# STM32F030 register map
File version: 1.0
Registers are 32-bit, read-write, reset 0x0 unless marked. A register's access mark holds for its fields unless they carry their own. Offsets are from the block's base; [hi:lo] are bit positions; {n}, {i} and the like mark numbered series.

## ADC — Analog-to-digital converter
Base 0x40012400
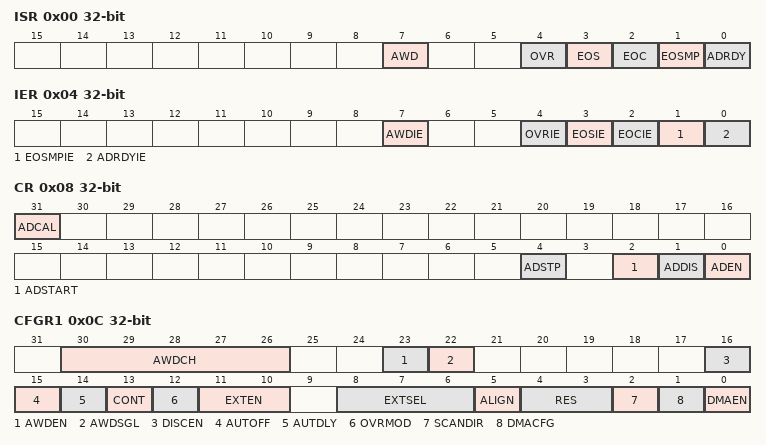
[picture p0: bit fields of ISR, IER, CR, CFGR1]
0x00 ISR — interrupt and status register
  [7] AWD — Analog watchdog flag
  [4] OVR — ADC overrun
  [3] EOS — End of sequence flag
  [2] EOC — End of conversion flag
  [1] EOSMP — End of sampling flag
  [0] ADRDY — ADC ready
0x04 IER — interrupt enable register
  [7] AWDIE — Analog watchdog interrupt enable
  [4] OVRIE — Overrun interrupt enable
  [3] EOSIE — End of conversion sequence interrupt enable
  [2] EOCIE — End of conversion interrupt enable
  [1] EOSMPIE — End of sampling flag interrupt enable
  [0] ADRDYIE — ADC ready interrupt enable
0x08 CR — control register
  [31] ADCAL — ADC calibration
  [4] ADSTP — ADC stop conversion command
  [2] ADSTART — ADC start conversion command
  [1] ADDIS — ADC disable command
  [0] ADEN — ADC enable command
0x0C CFGR1 — configuration register 1
  [30:26] AWDCH — Analog watchdog channel selection
  [23] AWDEN — Analog watchdog enable
  [22] AWDSGL — Enable the watchdog on a single channel or on all channels
  [16] DISCEN — Discontinuous mode
  [15] AUTOFF — Auto-off mode
  [14] AUTDLY — Auto-delayed conversion mode
  [13] CONT — Single / continuous conversion mode
  [12] OVRMOD — Overrun management mode
  [11:10] EXTEN — External trigger enable and polarity selection
  [8:6] EXTSEL — External trigger selection
  [5] ALIGN — Data alignment
  [4:3] RES — Data resolution
  [2] SCANDIR — Scan sequence direction
  [1] DMACFG — Direct memery access configuration
  [0] DMAEN — Direct memory access enable
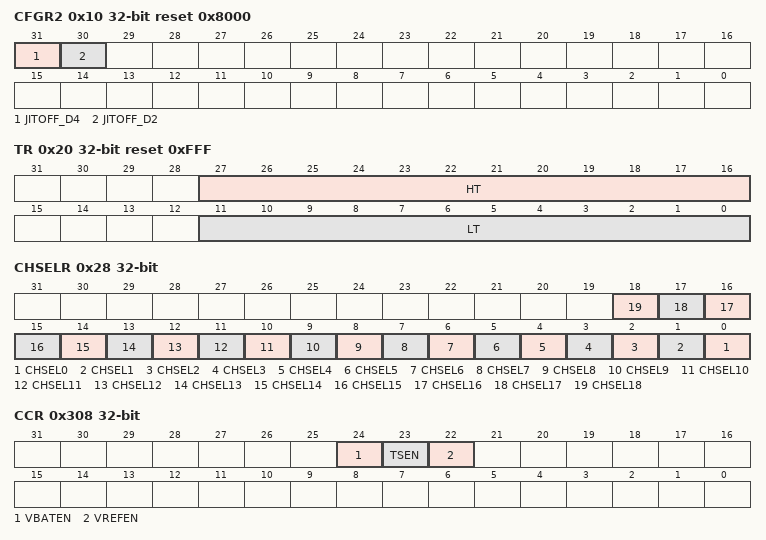
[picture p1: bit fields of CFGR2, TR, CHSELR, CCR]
0x10 CFGR2 reset 0x8000 — configuration register 2
  [31] JITOFF_D4, [30] JITOFF_D2
0x14 SMPR — sampling time register
  [2:0] SMPR — Sampling time selection
0x20 TR reset 0xFFF — watchdog threshold register
  [27:16] HT — Analog watchdog higher threshold
  [11:0] LT — Analog watchdog lower threshold
0x28 CHSELR — channel selection register
  [n] CHSEL{n} (n=0..18) — Channel-x selection
0x40 DR ro — data register
  [15:0] DATA — Converted data
0x308 CCR — common configuration register
  [24] VBATEN — VBAT enable
  [23] TSEN — Temperature sensor enable
  [22] VREFEN — Temperature sensor and VREFINT enable

## TIM16 — General-purpose-timers
Base 0x40014400
Same registers: TIM17 0x40014800
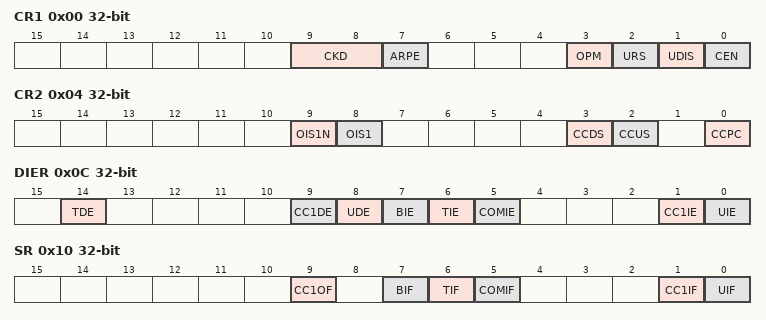
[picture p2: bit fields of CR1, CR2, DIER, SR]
0x00 CR1 — control register 1
  [9:8] CKD — Clock division
  [7] ARPE — Auto-reload preload enable
  [3] OPM — One-pulse mode
  [2] URS — Update request source
  [1] UDIS — Update disable
  [0] CEN — Counter enable
0x04 CR2 — control register 2
  [9] OIS1N — Output Idle state 1
  [8] OIS1 — Output Idle state 1
  [3] CCDS — Capture/compare DMA selection
  [2] CCUS — Capture/compare control update selection
  [0] CCPC — Capture/compare preloaded control
0x0C DIER — DMA/Interrupt enable register
  [14] TDE — Trigger DMA request enable
  [9] CC1DE — Capture/Compare 1 DMA request enable
  [8] UDE — Update DMA request enable
  [7] BIE — Break interrupt enable
  [6] TIE — Trigger interrupt enable
  [5] COMIE — COM interrupt enable
  [1] CC1IE — Capture/Compare 1 interrupt enable
  [0] UIE — Update interrupt enable
0x10 SR — status register
  [9] CC1OF — Capture/Compare 1 overcapture flag
  [7] BIF — Break interrupt flag
  [6] TIF — Trigger interrupt flag
  [5] COMIF — COM interrupt flag
  [1] CC1IF — Capture/compare 1 interrupt flag
  [0] UIF — Update interrupt flag
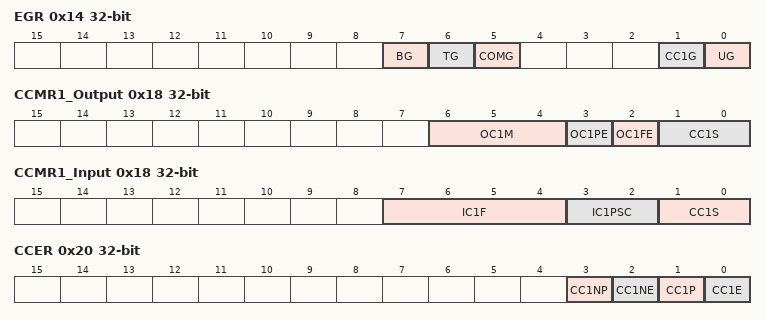
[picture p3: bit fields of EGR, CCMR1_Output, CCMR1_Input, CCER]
0x14 EGR wo — event generation register
  [7] BG — Break generation
  [6] TG — Trigger generation
  [5] COMG — Capture/Compare control update generation
  [1] CC1G — Capture/compare 1 generation
  [0] UG — Update generation
0x18 CCMR1_Output — capture/compare mode register (output mode)
  [6:4] OC1M — Output Compare 1 mode
  [3] OC1PE — Output Compare 1 preload enable
  [2] OC1FE — Output Compare 1 fast enable
  [1:0] CC1S — Capture/Compare 1 selection
0x18 CCMR1_Input (alternate view of CCMR1_Output) — capture/compare mode register 1 (input mode)
  [7:4] IC1F — Input capture 1 filter
  [3:2] IC1PSC — Input capture 1 prescaler
  [1:0] CC1S — Capture/Compare 1 selection
0x20 CCER — capture/compare enable register
  [3] CC1NP — Capture/Compare 1 output Polarity
  [2] CC1NE — Capture/Compare 1 complementary output enable
  [1] CC1P — Capture/Compare 1 output Polarity
  [0] CC1E — Capture/Compare 1 output enable
0x24 CNT — counter
  [15:0] CNT — counter value
0x28 PSC — prescaler
  [15:0] PSC — Prescaler value
0x2C ARR — auto-reload register
  [15:0] ARR — Auto-reload value
0x30 RCR — repetition counter register
  [7:0] REP — Repetition counter value
0x34 CCR1 — capture/compare register 1
  [15:0] CCR1 — Capture/Compare 1 value
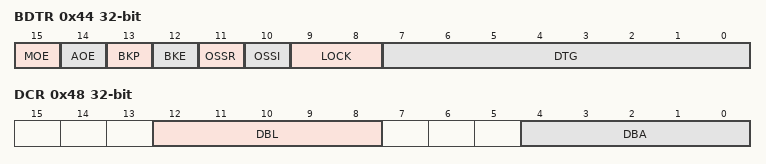
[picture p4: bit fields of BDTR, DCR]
0x44 BDTR — break and dead-time register
  [15] MOE — Main output enable
  [14] AOE — Automatic output enable
  [13] BKP — Break polarity
  [12] BKE — Break enable
  [11] OSSR — Off-state selection for Run mode
  [10] OSSI — Off-state selection for Idle mode
  [9:8] LOCK — Lock configuration
  [7:0] DTG — Dead-time generator setup
0x48 DCR — DMA control register
  [12:8] DBL — DMA burst length
  [4:0] DBA — DMA base address
0x4C DMAR — DMA address for full transfer
  [15:0] DMAB — DMA register for burst accesses

## Flash
Base 0x40022000
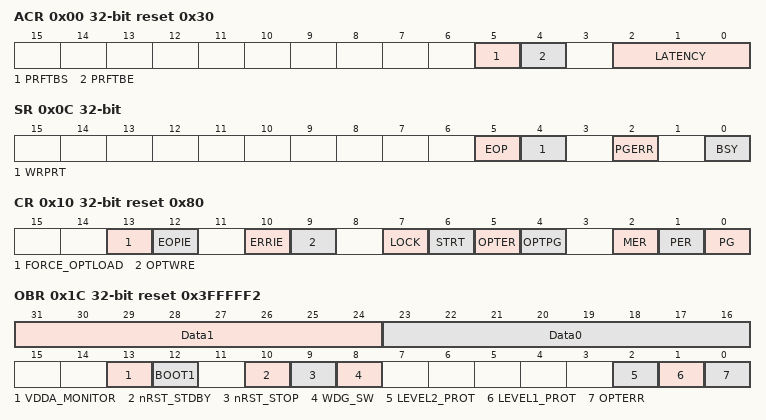
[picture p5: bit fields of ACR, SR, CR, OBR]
0x00 ACR access per field reset 0x30 — Flash access control register
  [5] PRFTBS ro, [4] PRFTBE rw, [2:0] LATENCY rw
0x04 KEYR wo — Flash key register
  [31:0] FKEYR — Flash Key
0x08 OPTKEYR wo — Flash option key register
  [31:0] OPTKEYR — Option byte key
0x0C SR access per field — Flash status register
  [5] EOP rw — End of operation
  [4] WRPRT rw — Write protection error
  [2] PGERR rw — Programming error
  [0] BSY ro — Busy
0x10 CR reset 0x80 — Flash control register
  [13] FORCE_OPTLOAD — Force option byte loading
  [12] EOPIE — End of operation interrupt enable
  [10] ERRIE — Error interrupt enable
  [9] OPTWRE — Option bytes write enable
  [7] LOCK
  [6] STRT — Start
  [5] OPTER — Option byte erase
  [4] OPTPG — Option byte programming
  [2] MER — Mass erase
  [1] PER — Page erase
  [0] PG — Programming
0x14 AR wo — Flash address register
  [31:0] FAR — Flash address
0x1C OBR ro reset 0x3FFFFF2 — Option byte register
  [31:24] Data1
  [23:16] Data0
  [13] VDDA_MONITOR
  [12] BOOT1
  [10] nRST_STDBY
  [9] nRST_STOP
  [8] WDG_SW
  [2] LEVEL2_PROT — Level 2 protection status
  [1] LEVEL1_PROT — Level 1 protection status
  [0] OPTERR — Option byte error
0x20 WRPR ro reset 0xFFFFFFFF — Write protection register
  [31:0] WRP — Write protect

## DBGMCU — Debug support
Base 0x40015800
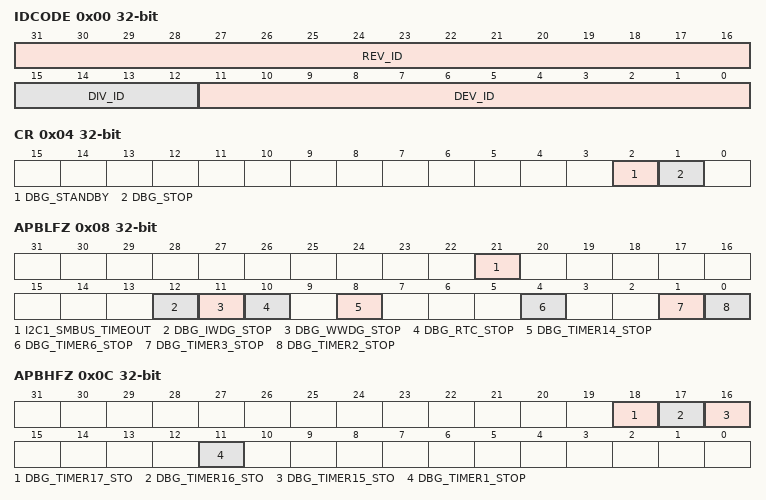
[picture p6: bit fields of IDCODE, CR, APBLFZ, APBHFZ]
0x00 IDCODE ro — MCU Device ID Code Register
  [31:16] REV_ID — Revision Identifier
  [15:12] DIV_ID — Division Identifier
  [11:0] DEV_ID — Device Identifier
0x04 CR — Debug MCU Configuration Register
  [2] DBG_STANDBY — Debug Standby Mode
  [1] DBG_STOP — Debug Stop Mode
0x08 APBLFZ — APB Low Freeze Register
  [21] I2C1_SMBUS_TIMEOUT — SMBUS timeout mode stopped when Core is halted
  [12] DBG_IWDG_STOP — Debug Independent Wachdog stopped when Core is halted
  [11] DBG_WWDG_STOP — Debug Window Wachdog stopped when Core is halted
  [10] DBG_RTC_STOP — Debug RTC stopped when Core is halted
  [8] DBG_TIMER14_STOP — Debug Timer 14 stopped when Core is halted
  [4] DBG_TIMER6_STOP — Debug Timer 6 stopped when Core is halted
  [1] DBG_TIMER3_STOP — Debug Timer 3 stopped when Core is halted
  [0] DBG_TIMER2_STOP — Debug Timer 2 stopped when Core is halted
0x0C APBHFZ — APB High Freeze Register
  [18] DBG_TIMER17_STO — Debug Timer 17 stopped when Core is halted
  [17] DBG_TIMER16_STO — Debug Timer 16 stopped when Core is halted
  [16] DBG_TIMER15_STO — Debug Timer 15 stopped when Core is halted
  [11] DBG_TIMER1_STOP — Debug Timer 1 stopped when Core is halted
